# i2c_wrap: IP-XACT component
VLNV tenstorrent.com:ocah:i2c_wrap:1.0

## Address spaces and blocks
i2c_wrap_mmap.i2c_wrap: base 'h0, range 'he0c, width 32

## Registers
Registers are 32-bit, read-write, reset 0x0 unless marked. A register's access mark holds for its fields unless they carry their own. Offsets are from the block's base; lines under a group give offsets from that group; [hi:lo] are bit positions; {n}, {i} and the like mark numbered series; 'fields as' and 'values as' point back to an identical list; <NAME> marks a mode.

## i2c_wrap_mmap.i2c_wrap — Wrapper address map instantiating the per-controller I2C register blocks and shared control.
Base 0x00000000
{0x0+0x200*i} i2c[{i}] (i=0..2) group — Interrupt status, enable, and test registers for a single I2C controller and target.
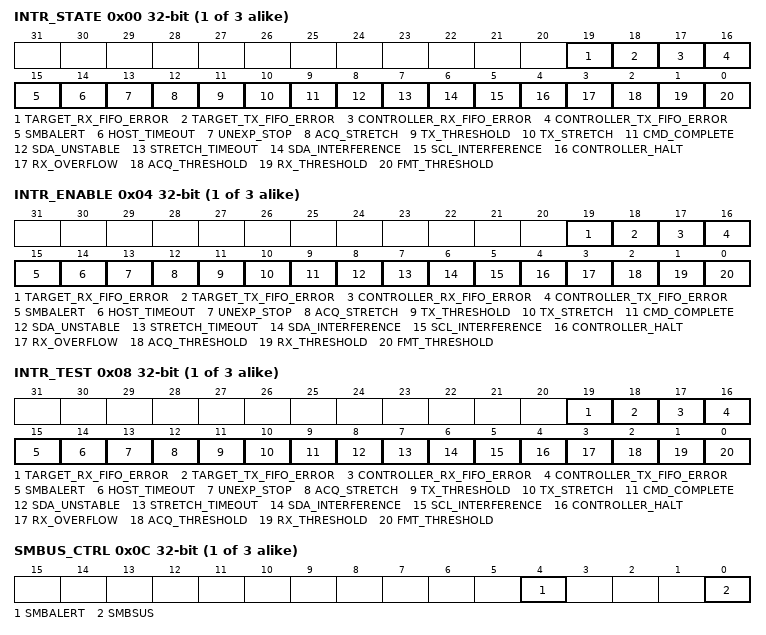
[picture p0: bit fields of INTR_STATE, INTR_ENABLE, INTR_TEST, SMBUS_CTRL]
  0x00 INTR_STATE access per field — Interrupt Status Register
    [19] TARGET_RX_FIFO_ERROR rw write-1-clears — Target Mode interrupt: asserted when the Target RX FIFO has a parity error. Write `1` to clear.
    [18] TARGET_TX_FIFO_ERROR rw write-1-clears — Target Mode interrupt: asserted when the Target TX FIFO has a parity error. Write `1` to clear.
    [17] CONTROLLER_RX_FIFO_ERROR rw write-1-clears — Controller Mode interrupt: asserted when the Controller RX FIFO has a parity error. Write `1` to clear.
    [16] CONTROLLER_TX_FIFO_ERROR rw write-1-clears — Controller Mode interrupt: asserted when the Controller TX FIFO has a parity error. Write `1` to clear.
    [15] SMBALERT rw write-1-clears — Controller Mode interrupt: asserted when `smbalert_ni` is asserted. Write `1` to clear.
    [14] HOST_TIMEOUT rw write-1-clears — Target Mode interrupt: asserted when the controller stops generating the clock longer than `HOST_TIMEOUT_CTRL.VAL`. Write `1` to clear.
    [13] UNEXP_STOP rw write-1-clears — Target Mode interrupt: asserted when the controller sends this target a STOP before this target NACKs. Write `1` to clear.
    [12] ACQ_STRETCH ro — Target Mode interrupt: remains asserted while the target is stretching the clock because 1) the Target RX FIFO is full or 2) the `TARGET_ACK_CTRL.NBYTES` count has reached `0` (only if `CTRL.ACK_CTRL_EN = 1`).
    [11] TX_THRESHOLD ro — Target Mode interrupt: remains asserted while the Target TX FIFO level is less than `TARGET_FIFO_CONFIG.TX_THRESH`.
    [10] TX_STRETCH ro — Target Mode interrupt: remains asserted while this target is stretching the clock or has halted. The flags in the `TARGET_EVENTS` register explain the reason(s) for clock stretching/halting. Clearing the `TARGET_EVENTS` flags clears this interrupt.
    [9] CMD_COMPLETE rw write-1-clears — Controller/Target Mode interrupt: asserted when this/the controller finishes generating a STOP or repeated START. Write `1` to clear.
    [8] SDA_UNSTABLE rw write-1-clears — Controller Mode interrupt: asserted when the target fails to keep SDA stable during a transmission. Write `1` to clear.
    [7] STRETCH_TIMEOUT rw write-1-clears — Controller Mode interrupt: asserted when the target stretches the clock longer than `TIMEOUT_CTRL.VAL` (valid only when `TIMEOUT_CTRL.MODE = 0`). Write `1` to clear.
    [6] SDA_INTERFERENCE rw write-1-clears — Controller Mode interrupt: asserted when SDA is unexpectedly pulled LOW by another controller. Write `1` to clear.
    [5] SCL_INTERFERENCE rw write-1-clears — Controller Mode interrupt: asserted when SCL is unexpectedly pulled LOW by another controller. Write `1` to clear.
    [4] CONTROLLER_HALT ro — Controller Mode interrupt: remains asserted while this controller halts. The flags in the `CONTROLLER_EVENTS` register explain the reason(s) for the halting. Clearing the `CONTROLLER_EVENTS` flags clears this interrupt.
    [3] RX_OVERFLOW rw write-1-clears — Controller Mode interrupt: asserted when the Controller RX FIFO overflows. Write `1` to clear.
    [2] ACQ_THRESHOLD ro — Target Mode interrupt: remains asserted while the Target RX FIFO level is greater than `TARGET_FIFO_CONFIG.ACQ_THRESH`.
    [1] RX_THRESHOLD ro — Controller Mode interrupt: remains asserted while the Controller RX FIFO level is greater than `HOST_FIFO_CONFIG.RX_THRESH`.
    [0] FMT_THRESHOLD ro — Controller Mode interrupt: remains asserted while the Controller TX FIFO level is less than `HOST_FIFO_CONFIG.FMT_THRESH`.
  0x04 INTR_ENABLE — Interrupt Enable Register
    [19] TARGET_RX_FIFO_ERROR — Enables the `TARGET_RX_FIFO_ERROR` interrupt.
    [18] TARGET_TX_FIFO_ERROR — Enables the `TARGET_TX_FIFO_ERROR` interrupt.
    [17] CONTROLLER_RX_FIFO_ERROR — Enables the `CONTROLLER_RX_FIFO_ERROR` interrupt.
    [16] CONTROLLER_TX_FIFO_ERROR — Enables the `CONTROLLER_TX_FIFO_ERROR` interrupt.
    [15] SMBALERT — Enables the `SMBALERT` interrupt.
    [14] HOST_TIMEOUT — Enables the `HOST_TIMEOUT` interrupt.
    [13] UNEXP_STOP — Enables the `UNEXP_STOP` interrupt.
    [12] ACQ_STRETCH — Enables the `ACQ_STRETCH` interrupt.
    [11] TX_THRESHOLD — Enables the `TX_THRESHOLD` interrupt.
    [10] TX_STRETCH — Enables the `TX_STRETCH` interrupt.
    [9] CMD_COMPLETE — Enables the `CMD_COMPLETE` interrupt.
    [8] SDA_UNSTABLE — Enables the `SDA_UNSTABLE` interrupt.
    [7] STRETCH_TIMEOUT — Enables the `STRETCH_TIMEOUT` interrupt.
    [6] SDA_INTERFERENCE — Enables the `SDA_INTERFERENCE` interrupt.
    [5] SCL_INTERFERENCE — Enables the `SCL_INTERFERENCE` interrupt.
    [4] CONTROLLER_HALT — Enables the `CONTROLLER_HALT` interrupt.
    [3] RX_OVERFLOW — Enables the `RX_OVERFLOW` interrupt.
    [2] ACQ_THRESHOLD — Enables the `ACQ_THRESHOLD` interrupt.
    [1] RX_THRESHOLD — Enables the `RX_THRESHOLD` interrupt.
    [0] FMT_THRESHOLD — Enables the `FMT_THRESHOLD` interrupt.
  0x08 INTR_TEST access per field — Interrupt Test Register
    [19] TARGET_RX_FIFO_ERROR wo — Writing `1` forces the `TARGET_RX_FIFO_ERROR` interrupt.
    [18] TARGET_TX_FIFO_ERROR wo — Writing `1` forces the `TARGET_TX_FIFO_ERROR` interrupt.
    [17] CONTROLLER_RX_FIFO_ERROR wo — Writing `1` forces the `CONTROLLER_RX_FIFO_ERROR` interrupt.
    [16] CONTROLLER_TX_FIFO_ERROR wo — Writing `1` forces the `CONTROLLER_TX_FIFO_ERROR` interrupt.
    [15] SMBALERT wo — Writing `1` forces the `SMBALERT` interrupt.
    [14] HOST_TIMEOUT wo — Writing `1` forces the `HOST_TIMEOUT` interrupt.
    [13] UNEXP_STOP wo — Writing `1` forces the `UNEXP_STOP` interrupt.
    [12] ACQ_STRETCH rw — Writing `1` forces the `ACQ_STRETCH` interrupt. Writing `0` releases it.
    [11] TX_THRESHOLD rw — Writing `1` forces the `TX_THRESHOLD` interrupt. Writing `0` releases it.
    [10] TX_STRETCH rw — Writing `1` forces the `TX_STRETCH` interrupt. Writing a `0` releases it.
    [9] CMD_COMPLETE wo — Writing `1` forces the `CMD_COMPLETE` interrupt.
    [8] SDA_UNSTABLE wo — Writing `1` forces the `SDA_UNSTABLE` interrupt.
    [7] STRETCH_TIMEOUT wo — Writing `1` forces the `STRETCH_TIMEOUT` interrupt.
    [6] SDA_INTERFERENCE wo — Writing `1` forces the `SDA_INTERFERENCE` interrupt.
    [5] SCL_INTERFERENCE wo — Writing `1` forces the `SCL_INTERFERENCE` interrupt.
    [4] CONTROLLER_HALT rw — Writing `1` forces the `CONTROLLER_HALT` interrupt. Writing `0` releases it.
    [3] RX_OVERFLOW wo — Writing `1` forces the `RX_OVERFLOW` interrupt.
    [2] ACQ_THRESHOLD rw — Writing `1` forces the `ACQ_THRESHOLD` interrupt. Writing `0` releases it.
    [1] RX_THRESHOLD rw — Writing `1` forces the `RX_THRESHOLD` interrupt. Writing `0` releases it.
    [0] FMT_THRESHOLD rw — Writing `1` forces the `FMT_THRESHOLD` interrupt. Writing `0` releases it.
  0x0C SMBUS_CTRL — SMBus Control Register
    [4] SMBALERT — Target Mode control: asserts the `smbalert_no` output. This bit clears itself when the controller addresses this target.
    [0] SMBSUS — Controller Mode control: asserts the `smbsus_no` output.
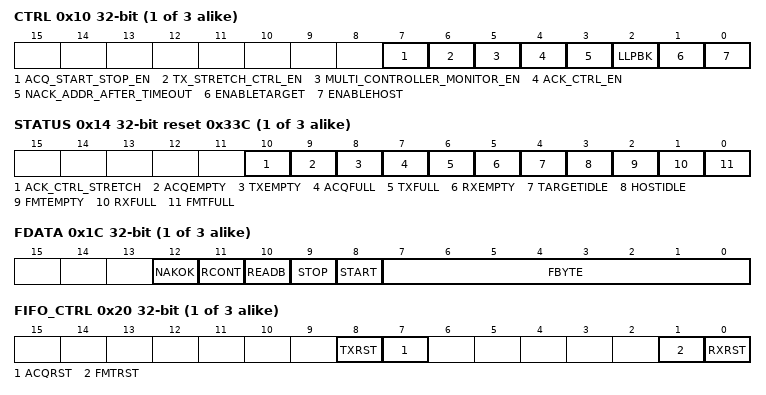
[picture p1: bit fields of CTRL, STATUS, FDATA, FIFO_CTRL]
  0x10 CTRL — Control Register
    [7] ACQ_START_STOP_EN — ACQ FIFO Start/Stop Enable (Target Mode only): * `0` - Start/Stop symbols are NOT written into the ACQ FIFO. The firmware should rely on `TARGET_EVENTS.START_DETECT` and `TARGET_EVENTS.STOP_DETECT` flags to detect Start/Stop events. * `1` - Start/Stop symbols ARE written into the ACQ FIFO (legacy behavior). When a START (or repeated START) is detected, an `ACQ_START` or `ACQ_RESTART` entry is written. When a STOP is detected, an `ACQ_STOP` or `ACQ_NACK_STOP` entry is written.
    [6] TX_STRETCH_CTRL_EN — Target mode control: enables the Software TX Stretch Control Mechanism. If this bit is: * `0` - Automatic TX Stretch: When this target receives a READ address byte, it only stretches the clock if the TX FIFO is empty; otherwise, it pops the FIFO and transmits the data byte. The target never sets the `TARGET_EVENTS` register flags in this mode. * `1` - Software TX Stretch Mode: When this target receives a READ address, it always stretches the clock and sets the `TARGET_EVENTS.TX_PENDING` flag. The software can: 1. confirm the release and transmission of the TX FIFO data by writing a 1 to clear the `TARGET_EVENTS.TX_PENDING` flag; or 2. reset the TX FIFO by writing 1 to `FIFO_CTRL.TXRST` and load in new data via the `TXDATA` register--useful whenthe READ address is targeting a different function of the target. In this mode, the target always sets the `TARGET_EVENTS` register flags.
    [5] MULTI_CONTROLLER_MONITOR_EN — Global control: enables the Bus Monitor. Set this bit to `1` only in a multi-controller environment. If a `0`->`1` transition happens while `ENABLEHOST` and `ENABLETARGET` are both `0`, the Bus Monitor will enable and begin in the 'Bus Busy' state. To transition to a 'Bus Free' state, `HOST_TIMEOUT_CTRL` must be nonzero so the Bus Monitor may count out idle cycles to confirm the freedom to transmit. In addition, the Bus Monitor will track whether the bus is free based on the enabled timeouts and detected STOP symbols. For Multi-Controller Mode, ensure `MULTI_CONTROLLER_MONITOR_EN` becomes `1` no later than `ENABLEHOST` or `ENABLETARGET`. This bit can be set at the same time as either or both of the other two, though. Note that if `MULTI_CONTROLLER_MONITOR_EN` is set after `ENABLEHOST` or `ENABLETARGET`, the Bus Monitor will begin in the 'Bus Free' state instead. This would violate the proper protocol for a controller to join a multi-controller environment. However, if this controller is known to be the first to join, this ordering will enable skipping the idle wait. When `0`, the bus monitor will report that the bus is always free, so the Controller FSM is never blocked from transmitting.
    [4] ACK_CTRL_EN — Target Mode control: enables the Software ACK Control Mechanism. If this bit is: * `0` - This target ACKs a data byte whenever the ACQ FIFO has space. * `1` - This target ACKs the first `TARGET_ACK_CTRL.NBYTES` bytes. If another byte arrives, this target stretches the clock and awaits software intervention (and asserts `STATUS.ACK_CTRL_STRETCH`). The software can 1. accept the new byte(s) by reloading the `TARGET_ACK_CTRL.NBYTES` counter; or 2. reject the new byte(s) by writing `1` to `TARGET_ACK_CTRL.NACK` (useful for SMBus).
    [3] NACK_ADDR_AFTER_TIMEOUT — Target Mode control: NACK address after timeout. If this bit is: * `0` - This target ACKs the address byte even if a Stretch Timeout occurs (useful for SMBus). * `1` - This target NACKs the address byte when a Stretch Timeout occurs.
    [2] LLPBK — Global control: enables line loop-back. In Controller Mode, the internal logic sees the `smbalert_ni` input as deasserted. In Target Mode, this target sends all received SDA data back out, and the internal logic sees received data as all 1's.
    [1] ENABLETARGET — Global control: configures this device's operating mode. * `ENABLEHOST = 1` and `ENABLETARGET = 0` — Controller Mode * `ENABLEHOST = 0` and `ENABLETARGET = 1` — Target Mode * `ENABLEHOST = 1` and `ENABLETARGET = 1` — Hybrid Mode * `ENABLEHOST = 0` and `ENABLETARGET = 0` — Monitor Mode
    [0] ENABLEHOST — Global control: configures this device's operating mode. * `ENABLEHOST = 1` and `ENABLETARGET = 0` — Controller Mode * `ENABLEHOST = 0` and `ENABLETARGET = 1` — Target Mode * `ENABLEHOST = 1` and `ENABLETARGET = 1` — Hybrid Mode * `ENABLEHOST = 0` and `ENABLETARGET = 0` — Monitor Mode
  0x14 STATUS ro reset 0x33C
    [10] ACK_CTRL_STRETCH — Target Mode status: indicates that this target is stretching the clock due to the Software ACK Control Mechanism. See `CTRL.ACK_CTRL_EN` for details.
    [9] ACQEMPTY — Target Mode status: Target RX FIFO empty.
    [8] TXEMPTY — Target Mode status: Target TX FIFO empty.
    [7] ACQFULL — Target Mode status: Target RX FIFO full.
    [6] TXFULL — Target Mode status: Target TX FIFO full.
    [5] RXEMPTY — Controller Mode status: Controller RX FIFO empty.
    [4] TARGETIDLE — Target Mode status: Target FSM idle.
    [3] HOSTIDLE — Controller Mode status: Controller FSM idle.
    [2] FMTEMPTY — Controller Mode status: Controller TX FIFO Empty.
    [1] RXFULL — Controller Mode status: Controller RX FIFO Full.
    [0] FMTFULL — Controller Mode status: Controller TX FIFO Full.
  0x18 RDATA ro — Controller RX FIFO Access Register (Controller Mode only)
    [7:0] DATA read-modifies — Reading this register pops the Controller RX FIFO.
  0x1C FDATA wo — Controller TX FIFO Access Register (Controller Mode only)
    [12] NAKOK — NACK OK. When set, this controller will not care if this byte is NACKed. It will not halt, set the `CONTROLLER_EVENTS.NACK` flag, or assert the `CONTROLLER_HALT` Interrupt. This behavior is useful for protocols like Serial Camera Control Bus (SCCB).
    [11] RCONT — Read continue/stop: * `0` — Read Stop: The controller NACKs the last data byte. Use this if this is the last READ in a sequence. * `1` — Read Continue: The controller ACKs the last data byte. Use this if this is an intermediate READ in a sequence.
    [10] READB — Read/write: * `0` - Issue WRITE transaction * `1` - Issue READ transaction
    [9] STOP — Generate a STOP condition on the bus after sending the byte.
    [8] START — Generate a START condition on the bus before sending the byte.
    [7:0] FBYTE — Writing to this register pushes an entry into the Controller TX FIFO. The meaning of this field depends on the value of the `READB` field: * `READB = 0` - This field is the WRITE data byte. * `READB = 1` - This field specifies the number of bytes to read from the target. Setting this field to 0 reads 256 bytes.
  0x20 FIFO_CTRL wo — FIFO Control Register
    [8] TXRST — Target Mode control: writing `1` resets the Target TX FIFO.
    [7] ACQRST — Target Mode control: writing `1` resets the Target RX FIFO.
    [1] FMTRST — Controller Mode control: writing `1` resets the Controller TX FIFO.
    [0] RXRST — Controller Mode control: writing `1` resets the Controller RX FIFO.
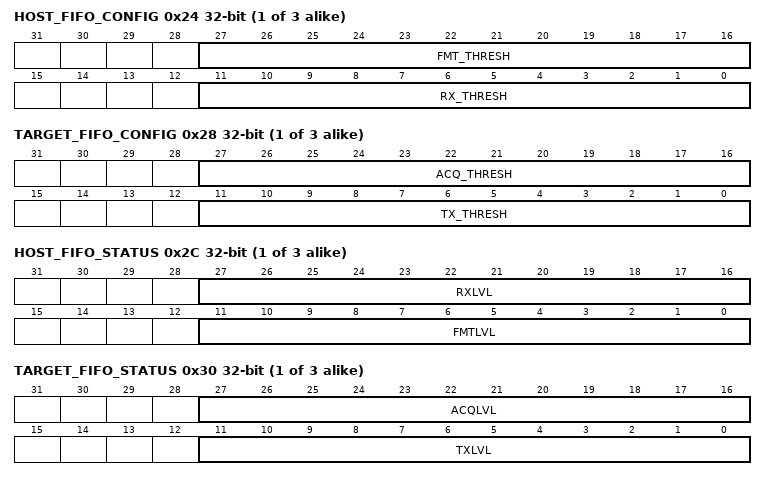
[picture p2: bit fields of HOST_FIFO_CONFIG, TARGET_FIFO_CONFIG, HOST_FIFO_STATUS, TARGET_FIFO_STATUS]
  0x24 HOST_FIFO_CONFIG — Controller FIFO Configuration Register (Controller Mode only)
    [27:16] FMT_THRESH — The `FMT_THRESH` interrupt remains asserted while the Controller TX FIFO level is less than this setting.
    [11:0] RX_THRESH — The `RX_THRESH` interrupt remains asserted while the Controller RX FIFO level is greater than this setting.
  0x28 TARGET_FIFO_CONFIG — Target FIFOs Configuration Register (Target Mode only)
    [27:16] ACQ_THRESH — The `ACQ_THRESH` interrupt remains asserted while the Target RX FIFO level is greater than this setting.
    [11:0] TX_THRESH — The `TX_THRESH` interrupt remains asserted while the Target TX FIFO level is less than this setting.
  0x2C HOST_FIFO_STATUS ro reset not defined — Controller FIFOs Status Register (Controller Mode only)
    [27:16] RXLVL — Controller RX FIFO fill level, from 0 to the FIFO depth when full.
    [11:0] FMTLVL — Controller TX FIFO fill level, from 0 to the FIFO depth when full.
  0x30 TARGET_FIFO_STATUS ro — Target FIFOs Status Register (Target Mode only)
    [27:16] ACQLVL — Target RX FIFO fill level, from 0 to the FIFO depth when full.
    [11:0] TXLVL — Target TX FIFO fill level, from 0 to the FIFO depth when full.
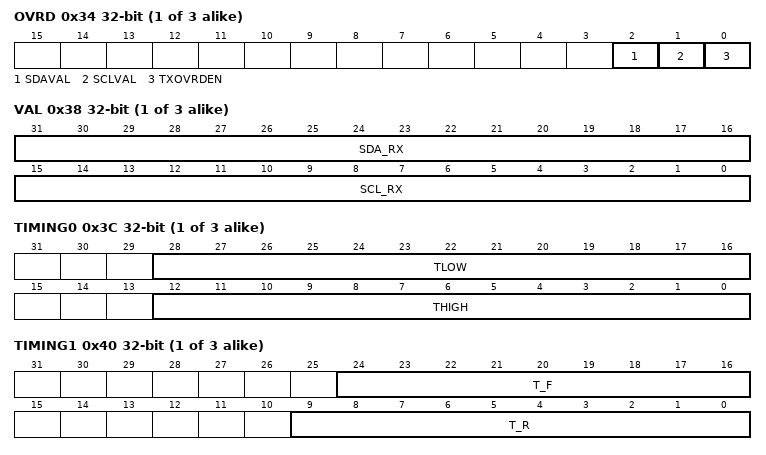
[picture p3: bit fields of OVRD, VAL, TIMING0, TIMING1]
  0x34 OVRD — Override Control Register
    [2] SDAVAL — Global control: SDA override value: * `0` - Pull the SDA line low * `1` - Release the SDA line
    [1] SCLVAL — Global control: SCL override value: * `0` - Pull the SCL line low * `1` - Release the SCL line
    [0] TXOVRDEN — Global control: enables control of the SDA and SCL lines through the `SDA_VAL` and `SCL_VAL` fields, respectively.
  0x38 VAL ro — Bus Oversampled Values Register
    [31:16] SDA_RX — Global status: contains the last 16 SDA over-sampled values. LSB is most recent.
    [15:0] SCL_RX — Global status: contains the last 16 SCL over-sampled values. LSB is most recent.
  0x3C TIMING0 — SCL LOW and HIGH Periods Register
    [28:16] TLOW — Global control: specifies the LOW period of SCL (`t_LOW`) in system clock cycles. Must be `≥ 2`. See Table 11 in the I2C Specification for more details. This field is sized to meet the I2C Standard-mode (100 kHz) minimum `t_LOW = 4.7 μs` requirement, assuming a 1 GHz system clock.
    [12:0] THIGH — Global control: specifies the HIGH period of SCL (`t_HIGH`) in system clock cycles. Must be `≥ 2`. See Table 11 in the I²C Specification for details. This field is sized to meet the I2C Standard-mode (100 kHz)'s minimum `t_HIGH = 4.0 μs` requirement, assuming a 1 GHz system clock.
  0x40 TIMING1 — Bus Rise and Fall Times Register
    [24:16] T_F — Global control: specifies the fall time of SDA and SCL (`t_f`) in system clock cycles. The fall time is measured from 70% to 30% of the signal swing. See Table 11 in the I2C Specification for more details. This field is sized to meet I2C Standard-mode (100 kHz)'s maximum `t_f = 300 ns` requirement, assuming a 1 GHz system clock.
    [9:0] T_R — Global control: specifies the rise time of SDA and SCL (`t_r`) in system clock cycles. The rise time is measured from 30% to 70% of the signal swing. See Table 11 in the I2C Specification for more details. This field is sized to meet I2C Standard-mode (100 kHz)'s maximum `t_r = 1000 ns` requirement, assuming a 1 GHz system clock.
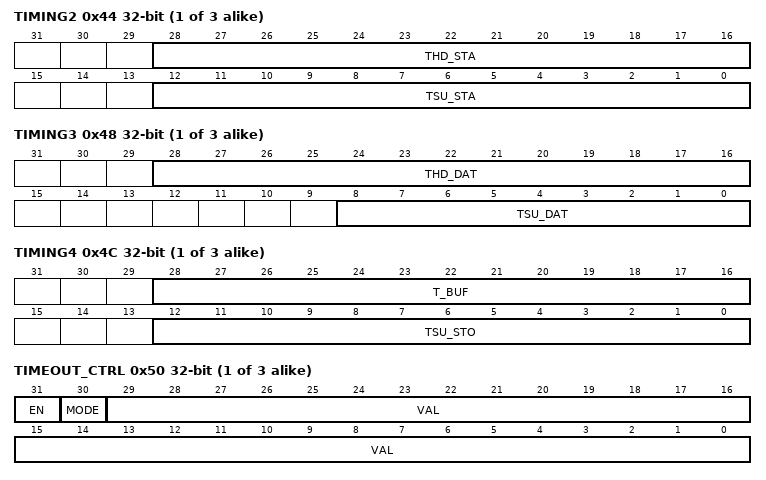
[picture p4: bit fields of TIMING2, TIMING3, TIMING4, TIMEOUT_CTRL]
  0x44 TIMING2 — START Condition Setup and Hold Times Register
    [28:16] THD_STA — Global control: specifies the setup time for a (repeated) START condition (`t_HD;STA`) in system clock cycles. See Table 11 in the I2C Specification for details. This field is sized to meet I2C Standard-mode (100 kHz)'s minimum `t_HD;STA = 4.0 μs` requirement, assuming a 1 GHz system clock.
    [12:0] TSU_STA — Global control: specifies the setup time for a repeated START condition (`t_SU;STA`) in system clock cycles. See Table 11 in the I2C Specification for details. This field is sized to meet I2C Standard-mode (100 kHz)'s minimum `t_SU;STA = 4.7 μs` requirement, assuming a 1 GHz system clock.
  0x48 TIMING3 — Data Setup and Hold Times Register
    [28:16] THD_DAT — Global control: specifies the data and (N)ACK bits hold time (`t_HD;DAT`) in system clock cycles. See Table 11 in the I2C Specification for details. This field is sized to meet the I2C Standard-mode (100 kHz)'s `t_HD;DAT = 5.0 μs` minimum requirement, assuming a 1 GHz system clock.
    [8:0] TSU_DAT — Target Mode control: specifies the data setup time (`t_SU;DAT`) in system clock cycles: after driving a data or ACK bit, the target holds SCL low for `TIMING1.T_R + TSU_DAT` before it releases a clock stretch. The controller does not use this field; its data setup is `TLOW - THD_DAT`, so a controller meets `t_SU;DAT` through `TIMING0.TLOW` and `TIMING3.THD_DAT`. See Table 11 in the I2C Specification for details. This field is sized to meet the I2C Standard-mode (100 kHz)'s `t_SU;DAT = 250 ns` minimum requirement, assuming a 1 GHz system clock.
  0x4C TIMING4 — STOP Condition Setup Time and Bus Free Time Register
    [28:16] T_BUF — Global control: specifies the time between a STOP and START condition (`t_BUF`) in system clock cycles. See Table 11 in the I²C Specification for details. This field is sized to meet I2C Standard-mode (100kHz)'s `t_BUF = 4.7 μs` minimum requirement, assuming a 1 GHz system clock.
    [12:0] TSU_STO — Global control: specifies the setup time for a STOP condition (`t_SU;STO`) in system clock cycles. See Table 11 in the I²C Specification for details. This field is sized to meet I2C Standard-mode (100 kHz)'s `t_SU;STO = 4.0 μs` minimum requirement, assuming a 1 GHz system clock.
  0x50 TIMEOUT_CTRL — Timeout Control Register
    [31] EN — Timeout Enable.
    [30] MODE — Global control: timeout mode. * `0` - Stretch Timeout (Controller Mode only). If the target stretches the clock for more time than `TIMEOUT_CTRL.VAL`, the `STRETCH_TIMEOUT` interrupt will be asserted. * `1` - Bus Timeout. If SCL is LOW for more time than `TIMEOUT_CTRL.VAL`: * In Controller Mode, the `CONTROLLER_EVENTS.BUS_TIMEOUT` flag will be asserted, triggering the `CONTROLLER_HALT` interrupt. * In Target Mode, the `TARGET_EVENTS.BUS_TIMEOUT` flag will be set, triggering the `TX_STRETCH` interrupt.
    [29:0] VAL — Global control: Specifies the timeout value in system clock cycles. The meaning of this field depends on `MODE`.
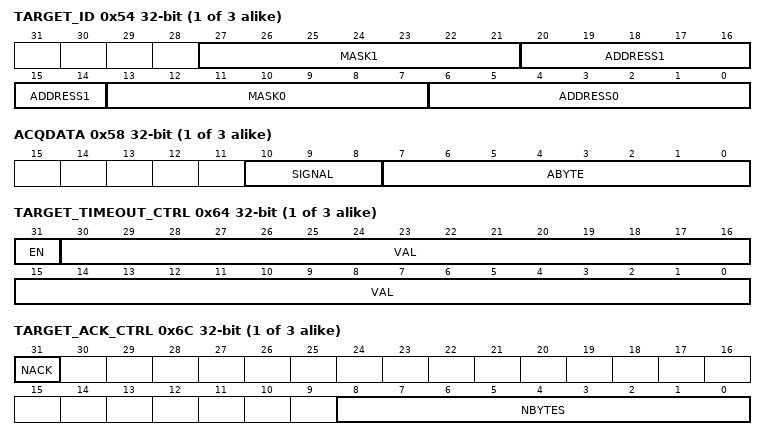
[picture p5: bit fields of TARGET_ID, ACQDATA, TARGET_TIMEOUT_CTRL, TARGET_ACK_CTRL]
  0x54 TARGET_ID — Target ID Register (Target Mode only)
    [27:21] MASK1 — ADDRESS1 mask.
    [20:14] ADDRESS1 — Target Address 1. This target responds if the 7-bit address matches `ADDRESS1 & MASK1`. `MASK1 = 0x0` disables this address.
    [13:7] MASK0 — ADDRESS0 mask.
    [6:0] ADDRESS0 — Target Address 0. This target responds if the 7-bit address matches `ADDRESS0 & MASK0`. `MASK0 = 0x0` disables this address.
  0x58 ACQDATA ro — Target RX FIFO Access Register (Target Mode only)
    [10:8] SIGNAL — This field indicates if this FIFO entry represents/is associated with control signal(s): * `0x0` - The entry is an ordinary data byte that has been ACKed. * `0x1` - The entry is an address byte preceded by a START. * `0x2` - The entry is a STOP condition following ACKed data bytes. * `0x3` - The entry is an address byte preceded by a repeated START. * `0x4` - The entry is a NACKed data byte. * `0x5` - The entry is an address byte preceded by a (repeated) START. However, the data bytes that followed this address byte were NACKed. * `0x6` - Error. A transaction preceding ended abnormally, for example, due to an unexpected STOP condition, a Bus or Stretch Timeout, a software NACK, or a lost arbitration. If the FIFO does not have enough space to record a complete transaction, an Error (`0x6`) entry may appear alone.
    [7:0] ABYTE read-modifies — Reading this register pops the ACQ FIFO. The meaning of this field depends on `SIGNAL`: * `SIGNAL = 0x0`, `0x1`, `0x3`, `0x4`, or `0x5` - This field contains an address or data byte sent by the controller. * `SIGNAL = 0x2`, `0x6` - This field is meaningless.
  0x5C TXDATA wo — Target TX FIFO Access Register (Target Mode only).
    [7:0] DATA — Writing to this register pushes data into the Target TX FIFO. The controller reads data from this FIFO during a READ transaction.
  0x60 HOST_TIMEOUT_CTRL — Controller Timeout Control Register
    [30:0] VAL — Target/Monitor Mode control: controller clock generation timeout value specified in system clock cycles. * Target Mode - If the controller stops generating the clock for more time than this setting, this target asserts the Controller Timeout Interrupt. * Monitor Mode - this field is required to be nonzero for the Bus Monitor to transition out of the initial Busy state. Set this field to `0x0` to disable this behavior.
  0x64 TARGET_TIMEOUT_CTRL — Target Timeout Control Register (Target Mode only)
    [31] EN — Enable Target Timeout.
    [30:0] VAL — When this target has stretched the clock for more time than this setting, this target will NACK incoming data bytes or release the SDA line for outgoing data bytes. The count is cumulative over an entire transaction. In other words, this is SMBus's cumulative target clock extension time. The behavior for the address byte is configurable via `CTRL.NACK_ADDR_AFTER_TIMEOUT`.
  0x68 TARGET_NACK_COUNT — Target NACK Count Register (Target Mode only)
    [7:0] TARGET_NACK_COUNT read-clears — Indicates the number of transactions NACKed by this target since the last read of this register, saturating at 255. This field can be used to track how many transactions were missed when the Target RX FIFO is full.
  0x6C TARGET_ACK_CTRL access per field — Target ACK Control Register (Target Mode only)
    [31] NACK wo — When `STATUS.ACK_CTRL_STRETCH = 1`, writing `1` to this field causes this target to NACK all bytes of the transaction. Effective only when `CTRL.ACK_CTRL_EN = 1`.
    [8:0] NBYTES rw — When `STATUS.ACK_CTRL_STRETCH = 1`, writing to this register specifies the number of bytes this target should ACK. The count decrements per byte ACKed. Effective only when `CTRL.ACK_CTRL_EN = 1`. See `CTRL.ACK_CTRL_EN` for details. This control field is used to implement SMBus's mid-transfer (N)ACK responses.
  0x70 ACQ_FIFO_NEXT_DATA ro — Target RX FIFO Next Byte Register (Target Mode only)
    [7:0] DATA — This field contains the next byte to be pushed into the Target RX FIFO, allowing software to decide whether to accept or reject it. Valid only when `STATUS.ACK_CTRL_STRETCH = 1`. See `CTRL.ACK_CTRL_EN` for details.
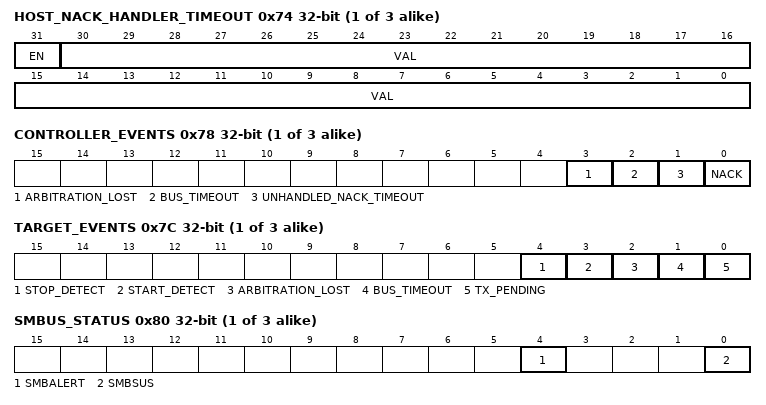
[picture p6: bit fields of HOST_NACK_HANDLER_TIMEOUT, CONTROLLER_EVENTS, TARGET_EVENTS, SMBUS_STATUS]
  0x74 HOST_NACK_HANDLER_TIMEOUT — Controller NACK Timeout Register (Controller Mode only)
    [31] EN — Enables Controller NACK Timeout.
    [30:0] VAL — Timeout value (specified in system clock cycles) for this controller Mode to automatically STOP a transaction when `CONTROLLER_EVENTS.NACK` is set.
  0x78 CONTROLLER_EVENTS — Controller Events Register (Controller Mode only)
    [3] ARBITRATION_LOST write-1-clears — Indicates that the controller has halted due to it losing an arbitration against another controller. This bit triggers the `CONTROLLER_HALT` interrupt. Writing `1` clears this bit.
    [2] BUS_TIMEOUT write-1-clears — Indicates that this controller has halted due to a Bus Timeout. See `TIMEOUT_CTRL` for details. This bit triggers the `CONTROLLER_HALT` interrupt. Writing `1` clears this bit.
    [1] UNHANDLED_NACK_TIMEOUT write-1-clears — Indicates that this controller has halted due to a Controller NACK Timeout. See `HOST_NACK_HANDLER_TIMEOUT` for details. This bit triggers the `CONTROLLER_HALT` interrupt. Writing `1` clears this bit.
    [0] NACK write-1-clears — Indicates that this controller has halted due to an unexpected NACK sent by the target. This behavior can be disabled by writing `1` to `FDATA.NAKOK`. This bit triggers the `CONTROLLER_HALT` interrupt. Writing `1` clears this bit.
  0x7C TARGET_EVENTS — Target Events Register (Target Mode)
    [4] STOP_DETECT write-1-clears — Stop Detect Flag (Target Mode only). Set to 1 by hardware when a STOP is detected while `CTRL.ENABLETARGET = 1`. Cleared when software writes 1.
    [3] START_DETECT write-1-clears — Start Detect Flag (Target Mode only). Set to 1 by hardware when a START (or repeated START) is detected while `CTRL.ENABLETARGET = 1`. Cleared when software writes 1.
    [2] ARBITRATION_LOST write-1-clears — Indicates that a controller has lost arbitration, causing a READ transaction to end. This bit triggers the `TX_STRETCH` interrupt. Writing `1` clears this bit.
    [1] BUS_TIMEOUT write-1-clears — Indicates that this target has halted due a Bus Timeout terminating a READ transaction. See `TIMEOUT_CTRL` for details. This bit triggers the `TX_STRETCH` interrupt. Writing `1` clears this bit.
    [0] TX_PENDING write-1-clears — Indicates that the target is stretching the clock due to receiving a READ address byte and waiting for software to confirm the release of the Target TX FIFO data. Valid only if `CTRL.TX_STRETCH_CTRL_EN = 1`. See `CTRL.TX_STRETCH_CTRL_EN` for details. This bit triggers the `TX_STRETCH` interrupt. Writing `1` clears this bit.
  0x80 SMBUS_STATUS ro
    [4] SMBALERT — Controller Mode status: indicates that the `smbalert_ni` input is asserted.
    [0] SMBSUS — Target Mode status: indicates that the `smbsus_ni` input is asserted.
0xE00 i2c_ctrl_regs group — Per-instance pad-function select, SMBus pad direction, and SMBus alert enable.
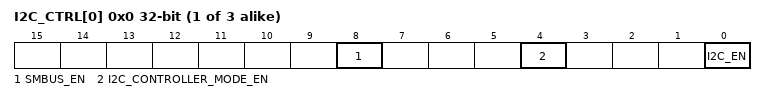
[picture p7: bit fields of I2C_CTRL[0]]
  {0x0+4j} I2C_CTRL[{j}] (j=0..2) — Control Register
    [8] SMBUS_EN — SMBus Enable. Gates the SMBus Alert signal.
    [4] I2C_CONTROLLER_MODE_EN — SMBus Pad Direction. When set, the SMBus alert pad is an input and the SMBus suspend pad is an output, as for an SMBus host. When clear, the alert pad is an output and the suspend pad is an input, as for an SMBus target. SCL and SDA are unaffected. Program it to agree with the core's CTRL.ENABLEHOST and CTRL.ENABLETARGET setting.
    [0] I2C_EN — I2C Pad Function Select. When set, the integration routes this instance's SCL, SDA, SMBus alert and SMBus suspend signals to their pads. Does not enable the I2C core; CTRL.ENABLEHOST and CTRL.ENABLETARGET select the core's operating mode.

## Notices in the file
SPDX-License-Identifier: Apache-2.0
SPDX-FileCopyrightText: 2026 Tenstorrent USA, Inc.
